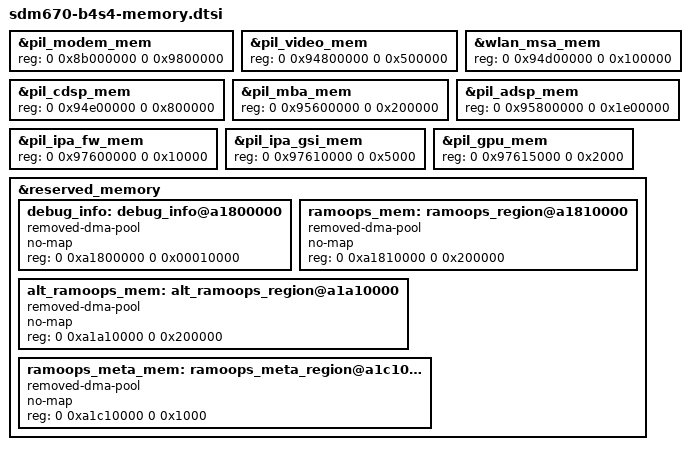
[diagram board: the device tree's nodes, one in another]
/* Copyright (c) 2017-2018, The Linux Foundation. All rights reserved.
 *
 * This program is free software; you can redistribute it and/or modify
 * it under the terms of the GNU General Public License version 2 and
 * only version 2 as published by the Free Software Foundation.
 *
 * This program is distributed in the hope that it will be useful,
 * but WITHOUT ANY WARRANTY; without even the implied warranty of
 * MERCHANTABILITY or FITNESS FOR A PARTICULAR PURPOSE.  See the
 * GNU General Public License for more details.
 */

/* B4S4 memory includes go here */

/*
 *the following carveout items are still defined in sdm670.dtsi:
 *region          address    size
 *==========      ========== =========
 *hyp_region:     0x85700000  0x600000
 *xbl_region:     0x85e00000  0x100000
 *removed_region: 0x85fc0000 0x2f40000
 *pil_camera_mem: 0x8ab00000  0x500000
 *qseecom_mem:    0x9e400000 0x1400000
 */

&pil_modem_mem {
	reg = <0 0x8b000000 0 0x9800000>;
};

&pil_video_mem {
	reg = <0 0x94800000 0 0x500000>;
};

&wlan_msa_mem {
	reg = <0 0x94d00000 0 0x100000>;
};

&pil_cdsp_mem {
	reg = <0 0x94e00000 0 0x800000>;
};

&pil_mba_mem {
	reg = <0 0x95600000 0 0x200000>;
};

&pil_adsp_mem {
	reg = <0 0x95800000 0 0x1e00000>;
};

&pil_ipa_fw_mem {
	reg = <0 0x97600000 0 0x10000>;
};

&pil_ipa_gsi_mem {
	reg = <0 0x97610000 0 0x5000>;
};

&pil_gpu_mem {
	reg = <0 0x97615000 0 0x2000>;
};

&reserved_memory {
	debug_info: debug_info@a1800000 {
		compatible = "removed-dma-pool";
		no-map;
		reg = <0 0xa1800000 0 0x00010000>;
	};

	ramoops_mem: ramoops_region@a1810000 {
		compatible = "removed-dma-pool";
		no-map;
		reg = <0 0xa1810000 0 0x200000>;
	};

	alt_ramoops_mem: alt_ramoops_region@a1a10000 {
		compatible = "removed-dma-pool";
		no-map;
		reg = <0 0xa1a10000 0 0x200000>;
	};

	ramoops_meta_mem: ramoops_meta_region@a1c10000 {
		compatible = "removed-dma-pool";
		no-map;
		reg = <0 0xa1c10000 0 0x1000>;
	};
};
